AUTOSAR XML (schema 00050)
standard types defined: Boolean, Float
package /ARRoot
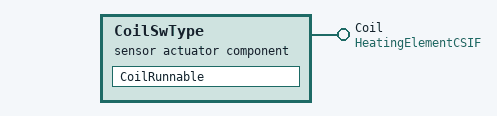
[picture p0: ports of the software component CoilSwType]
  sensor actuator sw component type CoilSwType
    provide port Coil: provided-interface=HeatingElementCSIF
    behavior CoilIB
      runnable CoilRunnable: external-triggering-point=Coil.TriggerForCoil
  swc implementation CoilTypeImpFile: programming-language=C, behavior=CoilIB
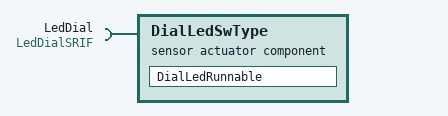
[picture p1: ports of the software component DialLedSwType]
  sensor actuator sw component type DialLedSwType
    require port LedDial: required-interface=LedDialSRIF
    behavior DialLedIB
      runnable DialLedRunnable: variable-access=accessed-variable=/ARRoot/LedDialSRIF/
  swc implementation DialLedTypeImpFile: programming-language=C, behavior=DialLedIB
  trigger interface ExternalTriggerForCoil
    trigger TriggerForCoil
  client server interface HeatingElementCSIF: client-server-operation=arguments=argument-data-prototype={type=Boolean, direction=OUT}
  swc implementation HeatingElementImpFile: programming-language=C, behavior=SeatHeatingIB
  sender receiver interface LedDialSRIF: data-elements=variable-data-prototype=type=Float
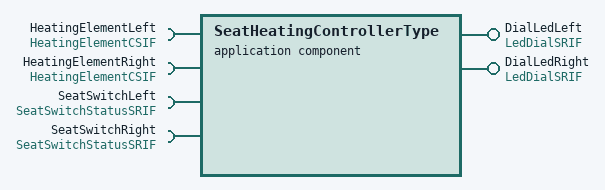
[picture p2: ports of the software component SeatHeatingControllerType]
  application sw component type SeatHeatingControllerType
    provide port DialLedLeft: provided-interface=LedDialSRIF
    provide port DialLedRight: provided-interface=LedDialSRIF
    4 x require port:
      HeatingElementLeft: required-interface=HeatingElementCSIF
      HeatingElementRight: required-interface=HeatingElementCSIF
      SeatSwitchLeft: required-interface=SeatSwitchStatusSRIF
      SeatSwitchRight: required-interface=SeatSwitchStatusSRIF
    behavior SeatHeatingIB
      6 x runnable:
        DialLedLeftRunnable: variable-access=accessed-variable=/ARRoot/LedDialSRIF/
        DialLedRightRunnable: variable-access=accessed-variable=/ARRoot/LedDialSRIF/
        HeatingElementLeftRunnable: synchronous-server-call-point=HeatingElementLeft.
        HeatingElementRightRunnable: synchronous-server-call-point=HeatingElementRight.
        SeatSwitchLeftRunnable: variable-access=accessed-variable=/ARRoot/SeatSwitchStatusSRIF/
        SeatSwitchRightRunnable: variable-access=accessed-variable=/ARRoot/SeatSwitchStatusSRIF/
  sender receiver interface SeatSwitchStatusSRIF: data-elements=variable-data-prototype=type=Boolean
